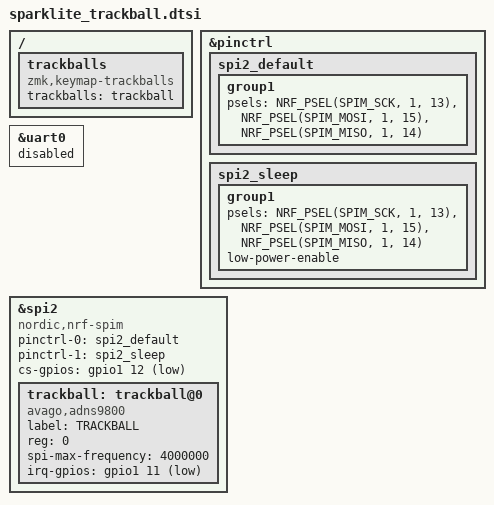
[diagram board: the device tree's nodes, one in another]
/*
 * Copyright (c) 2020 Pete Johanson
 *
 * SPDX-License-Identifier: MIT
 */

//---------------------------------------------------------
// SETUP NOTE:
// If trackball is activated on peripheral side, put below
// groups into central overlay file to make central aware
// trackball state changed from kepmap bindings.
//---------------------------------------------------------
// / {
// 	trackballs {
// 		compatible = "zmk,keymap-trackballs";
// 		trackballs = <&trackball>;
// 	};
// };
// &spi2 {
// 	status = "disabled";
// 	trackball: trackball@0 {
// 		status = "disabled";
// 		reg = <0>;
// 	};
// };
//--------------------------------------------------------

/ {
	trackballs {
		compatible = "zmk,keymap-trackballs";
		trackballs = <&trackball>;
	};
};

&pinctrl {
	spi2_default: spi2_default {
		group1 {
			psels = <NRF_PSEL(SPIM_SCK, 1, 13)>,
							<NRF_PSEL(SPIM_MOSI, 1, 15)>,
							<NRF_PSEL(SPIM_MISO, 1, 14)>;
		};
	};
	spi2_sleep: spi2_sleep {
		group1 {
			psels = <NRF_PSEL(SPIM_SCK, 1, 13)>,
							<NRF_PSEL(SPIM_MOSI, 1, 15)>,
							<NRF_PSEL(SPIM_MISO, 1, 14)>;
			low-power-enable;
		};
	};
};

// release gpio1 12 & 13 from xiao_ble-pinctrl.dtsi
// for &trackball { irq-gpios }
&uart0 {
	status = "disabled";
};

&spi2 {
	compatible = "nordic,nrf-spim";
	status = "disabled"; // <<< disabled in main .dtsi, okay in .overlay
	trackball: trackball@0 {
		compatible = "avago,adns9800";
		status = "disabled";
		label = "TRACKBALL";
		reg = <0>;
		spi-max-frequency = <4000000>;
	};
};

// Config custom gpios
&spi2 {
  status = "okay";
	pinctrl-0 = <&spi2_default>;
	pinctrl-1 = <&spi2_sleep>;
	pinctrl-names = "default", "sleep";
	cs-gpios = <&gpio1 12 GPIO_ACTIVE_LOW>;
};

&trackball {
  status = "okay";
  irq-gpios = <&gpio1 11 (GPIO_ACTIVE_LOW | GPIO_PULL_UP)>;
	// scroll-layer = <1>; // deprecapted
};

